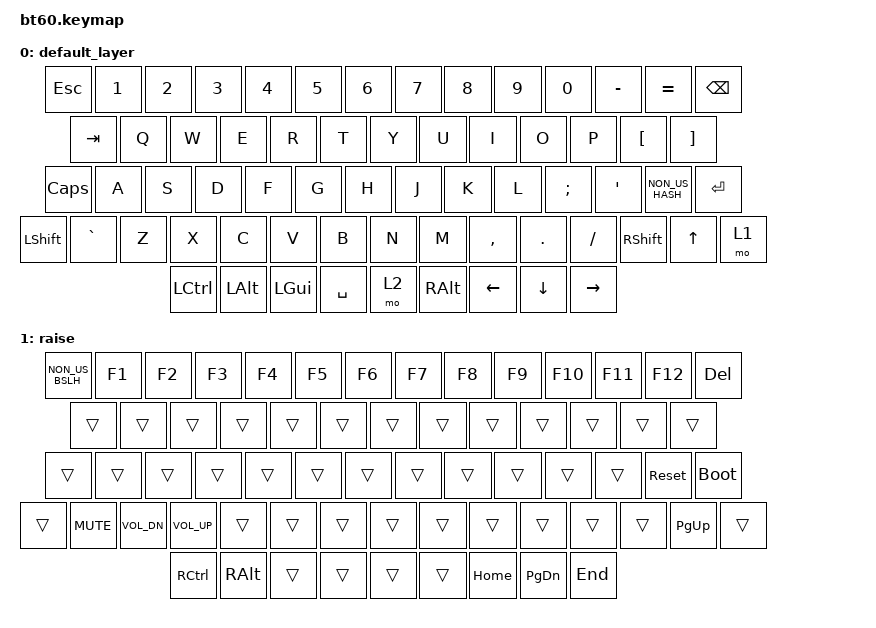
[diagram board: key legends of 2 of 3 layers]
#include <behaviors.dtsi>
#include <dt-bindings/zmk/keys.h>
#include <dt-bindings/zmk/bt.h>
#include <dt-bindings/zmk/rgb.h>
#include <dt-bindings/zmk/backlight.h>
#include <dt-bindings/zmk/outputs.h>

/ {
	keymap {
		compatible = "zmk,keymap";

		default_layer {
				// --------------------------------------------------------------------------------------------
				// | ESC |  1  |  2  |  3  |  4  |  5  |  6  |  7  |  8  |  9  |  0  |  -  |  =  |    BKSP    |
				// | TAB  |  Q  |  W  |  E  |  R  |  T  |  Y  |  U  |  I  |  O  |  P  |  [  |  ]  |           |
				// | CAPS  |  A  |  S  |  D  |  F  |  G  |  H  |  J  |  K  |  L  |  ;  |  '  |  #  |   ENTER  |
				// |  SHIFT |  \  |  Z  |  X  |  C  |  V  |  B  |  N  |  M  |  ,  |  .  |  /  | SHFT | UP | 1 |
				// |  CRTL  |  ALT  |  GUI  |            SPACE              |  2  | ALT | LEFT | DOWN | RIGHT |
				// --------------------------------------------------------------------------------------------
			bindings = <
				&kp ESC &kp N1 &kp N2 &kp N3 &kp N4 &kp N5 &kp N6 &kp N7 &kp N8 &kp N9 &kp N0 &kp MINUS &kp EQUAL &kp BSPC
				&kp TAB  &kp Q  &kp W  &kp E  &kp R  &kp T  &kp Y  &kp U  &kp  I    &kp  O  &kp  P   &kp LBKT &kp RBKT
				&kp CLCK  &kp A  &kp S  &kp D  &kp F  &kp G  &kp H  &kp J  &kp  K    &kp  L  &kp SEMI &kp SQT &kp NON_US_HASH     &kp ENTER
				&kp LSHFT  &kp GRAVE  &kp Z  &kp X  &kp C  &kp V  &kp B  &kp N  &kp M  &kp COMMA &kp DOT &kp FSLH &kp RSHFT &kp UP   &mo 1
				&kp LCTRL &kp LALT &kp LGUI            &kp SPACE                                 &mo 2   &kp RALT &kp LEFT  &kp DOWN &kp RIGHT
			>;
			sensor-bindings = <&inc_dec_kp C_VOL_UP C_VOL_DN>;
		};
		raise {
			bindings = <
				&kp NON_US_BSLH &kp F1 &kp F2 &kp F3 &kp F4 &kp F5 &kp F6 &kp F7 &kp F8 &kp F9 &kp F10 &kp F11 &kp F12   &kp DEL
				&trans &trans &trans &trans &trans &trans &trans &trans &trans &trans &trans &trans &trans
				&trans  &trans &trans &trans &trans &trans &trans &trans &trans &trans &trans  &trans &sys_reset &bootloader
				&trans   &kp C_MUTE &kp C_VOL_DN &kp C_VOL_UP &trans &trans &trans &trans &trans &trans &trans &trans &trans   &kp PG_UP &trans
				&kp RCTRL &kp RALT &trans                     &trans                                   &trans &trans &kp HOME &kp PG_DN &kp END
			>;
			sensor-bindings = <&inc_dec_kp C_VOL_UP C_VOL_DN>;
		};
		lower {
			bindings = <
				&bt BT_CLR &bt BT_SEL 1 &bt BT_SEL 2 &bt BT_SEL 3 &bt BT_SEL 4 &bt BT_SEL 5 &trans &trans &trans &trans &trans &trans &trans    &trans
				&out OUT_TOG   &trans &trans &trans &trans &trans &trans &trans &trans &trans &trans &trans &trans
				&rgb_ug RGB_TOG   &trans &trans &trans &trans &trans &trans &trans &trans &trans &trans  &trans       &trans
				&trans             &trans &trans &trans &trans &trans &trans &trans &trans &trans &trans &trans &trans &trans &trans
				&trans    &trans    &trans                    &trans                              &trans &trans &trans &trans &trans
			>;
			sensor-bindings = <&inc_dec_kp C_VOL_UP C_VOL_DN>;
		};
	};
};
